VERSION ""

NS_ :

BS_:

BU_: Arduino External

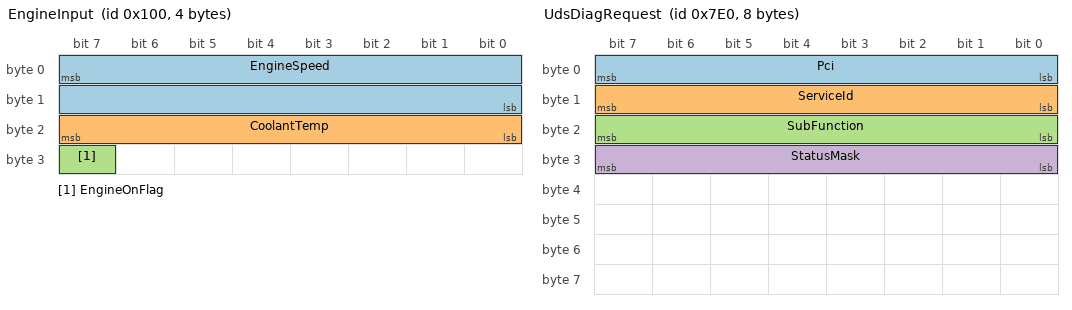
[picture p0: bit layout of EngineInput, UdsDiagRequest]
BO_ 256 EngineInput: 4 External
 SG_ EngineSpeed  : 7|16@0+ (1,0) [0|15000] "rpm"  Arduino
 SG_ CoolantTemp  : 23|8@0+ (1,0) [0|255]   "degC" Arduino
 SG_ EngineOnFlag : 31|1@0+ (1,0) [0|1]     ""     Arduino

BO_ 512 EngineStatus: 1 Arduino
 SG_ EngineState  : 7|8@0+  (1,0) [0|3]     ""     External

BO_ 2016 UdsDiagRequest: 8 External
 SG_ Pci         : 7|8@0+  (1,0) [0|255] "" Arduino
 SG_ ServiceId   : 15|8@0+ (1,0) [0|255] "" Arduino
 SG_ SubFunction : 23|8@0+ (1,0) [0|255] "" Arduino
 SG_ StatusMask  : 31|8@0+ (1,0) [0|255] "" Arduino

BO_ 2024 UdsDiagResponse: 8 Arduino
 SG_ Pci             : 7|8@0+   (1,0) [0|255]      "" External
 SG_ ServiceId       : 15|8@0+  (1,0) [0|255]      "" External
 SG_ SubFuncEcho     : 23|8@0+  (1,0) [0|255]      "" External
 SG_ StatusAvailMask : 31|8@0+  (1,0) [0|255]      "" External
 SG_ DtcCode         : 39|24@0+ (1,0) [0|16777215] "" External
 SG_ DtcCount        : 55|8@0+  (1,0) [0|255]      "" External
 SG_ DtcStatus       : 63|8@0+  (1,0) [0|255]      "" External

CM_ BO_ 256  "RX: External -> Arduino (CAN ID 0x100)";
CM_ BO_ 512  "TX: Arduino -> External (CAN ID 0x200)";
CM_ BO_ 2016 "TX: External -> Arduino (CAN ID 0x7E0) UDS diagnostic request (ISO 14229-1 / ISO 15765-2). リクエストは最大7バイトのため常に Single Frame (SF)。Pci=0x0N (N=UDS payload length), ServiceId=SID.";
CM_ BO_ 2024 "TX: Arduino -> External (CAN ID 0x7E8) UDS diagnostic response (ISO 15765-2 CanTp)。Short response (<=7byte): Single Frame (PCI=0x0N)。Long response (>=8byte): First Frame (PCI=0x10 0xNN) + Consecutive Frame (PCI=0x21..)。DBCシグナルはSF時のみ正確にデコードされる。FF/CF時はCangarooの生Hexビューで確認すること。";

CM_ SG_ 256 EngineSpeed  "Engine speed [rpm]. STARTING->RUNNING when >= 500. RUNNING->FAULT when < 100.";
CM_ SG_ 256 CoolantTemp  "Coolant temperature [degC]. RUNNING->FAULT when >= 100.";
CM_ SG_ 256 EngineOnFlag "Engine on request. OFF->STARTING when 1. Any state->OFF when 0.";
CM_ SG_ 512 EngineState  "Current engine state reported by Arduino every 3 seconds.";

CM_ SG_ 2016 Pci       "ISO 15765-2 PCI byte. Upper nibble=frame type (0x0=SingleFrame). Lower nibble=UDS payload length (1-7).";
CM_ SG_ 2016 ServiceId   "UDS Service ID (SID). 0x10=DiagnosticSessionControl, 0x11=ECUReset, 0x14=ClearDiagnosticInformation, 0x19=ReadDTCInformation, 0x22=ReadDataByIdentifier, 0x3E=TesterPresent.";
CM_ SG_ 2016 SubFunction "byte[2]. SID 0x19: subFunction (0x01=reportCount / 0x02=reportByMask). SID 0x14: groupOfDTC upper byte (0xFF for all).";
CM_ SG_ 2016 StatusMask  "byte[3]. SID 0x19: statusMask to filter DTCs. bit0=TF, bit2=PDTC, bit3=CDTC, bit4=TNCLC, bit5=TFSLC. Use 0x08 for confirmedDTC only.";
CM_ SG_ 2024 Pci         "ISO 15765-2 PCI byte. SF: 0x0N (lower nibble=UDS length). FF: 0x10 (next byte=total length). CF: 0x2N (N=sequence number).";
CM_ SG_ 2024 ServiceId   "UDS Response SID. Positive = request SID + 0x40. 0x50=SessionCtrl_Pos, 0x51=ECUReset_Pos, 0x54=ClearDTC_Pos, 0x59=ReadDTC_Pos, 0x62=ReadData_Pos, 0x7E=TesterPresent_Pos, 0x7F=NegativeResponse.";
CM_ SG_ 2024 SubFuncEcho     "byte[2]. Echo of request subFunction. 0x01=reportCount / 0x02=reportByMask.";
CM_ SG_ 2024 StatusAvailMask "byte[3]. statusAvailabilityMask: supported status bits (0x2D in this implementation). bit0=TF, bit2=PDTC, bit3=CDTC, bit4=TNCLC, bit5=TFSLC.";
CM_ SG_ 2024 DtcCode         "bytes[4-6] (24-bit). Valid when subFunc=0x02 (reportDTCByStatusMask). 24-bit DTC code. 0x000101=EngineOverheat, 0x000102=EngineStall, 0x000103=SpeedNoFlag, 0x000104=StartingTimeout.";
CM_ SG_ 2024 DtcCount        "byte[6]. Valid when subFunc=0x01 (reportNumberOfDTCByStatusMask). Number of DTCs matching statusMask (low byte).";
CM_ SG_ 2024 DtcStatus       "byte[7]. Valid when subFunc=0x02. DTC status byte. bit0=TF, bit2=PDTC, bit3=CDTC, bit4=TNCLC, bit5=TFSLC. 0x2D=FAILED_current, 0x2C=FAILED_history, 0x10=NotTested.";

 0 "OFF"
 1 "ON" ;

 0 "OFF"
 1 "STARTING"
 2 "RUNNING"
 3 "FAULT" ;

 16  "DiagnosticSessionControl"
 17  "ECUReset"
 20  "ClearDiagnosticInformation"
 25  "ReadDTCInformation"
 34  "ReadDataByIdentifier"
 62  "TesterPresent" ;

 1   "reportNumberOfDTCByStatusMask"
 2   "reportDTCByStatusMask"
 255 "groupOfDTC_All (0xFF for SID14)" ;

 80  "DiagnosticSessionControl_Pos"
 81  "ECUReset_Pos"
 84  "ClearDiagnosticInformation_Pos"
 89  "ReadDTCInformation_Pos"
 98  "ReadDataByIdentifier_Pos"
 126 "TesterPresent_Pos"
 127 "NegativeResponse" ;

 257 "ENGINE_OVERHEAT"
 258 "ENGINE_STALL"
 259 "ENGINE_SPEED_NO_FLAG"
 260 "ENGINE_STARTING_TIMEOUT" ;

 16  "NotTested_since_clear"
 44  "FAILED_history (PDTC+CDTC+TFSLC)"
 45  "FAILED_current (TF+PDTC+CDTC+TFSLC)" ;
